VERSION ""

NS_ :

BS_:

BU_: XXX

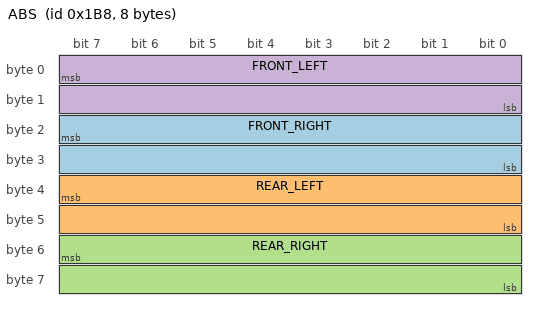
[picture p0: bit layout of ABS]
BO_ 440 ABS: 8 XXX
 SG_ FRONT_RIGHT : 23|16@0+ (0.0328,0) [0|65535] "kmh" XXX
 SG_ REAR_LEFT : 39|16@0+ (0.0328,0) [0|65535] "kmh" XXX
 SG_ REAR_RIGHT : 55|16@0+ (0.0328,0) [0|65535] "kmh" XXX
 SG_ FRONT_LEFT : 7|16@0+ (0.0328,0) [0|255] "kmh" XXX
